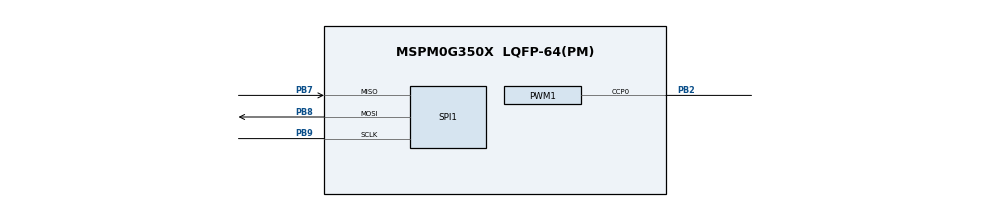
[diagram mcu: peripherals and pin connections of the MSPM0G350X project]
/**
 * @cliArgs --device "MSPM0G350X" --package "LQFP-64(PM)" --part "Default" --product "mspm0_sdk@2.00.01.00"
 * @versions {"tool":"1.20.0+3587"}
 */

/**
 * Import the modules used in this configuration.
 */
const GPIO   = scripting.addModule("/ti/driverlib/GPIO", {}, false);
const GPIO1  = GPIO.addInstance();
const PWM    = scripting.addModule("/ti/driverlib/PWM", {}, false);
const PWM1   = PWM.addInstance();
const SPI    = scripting.addModule("/ti/driverlib/SPI", {}, false);
const SPI1   = SPI.addInstance();
const SYSCTL = scripting.addModule("/ti/driverlib/SYSCTL");

/**
 * Write custom configuration values to the imported modules.
 */
GPIO1.$name                                 = "KEY";
GPIO1.port                                  = "PORTB";
GPIO1.associatedPins.create(2);
GPIO1.associatedPins[0].$name               = "freq";
GPIO1.associatedPins[0].direction           = "INPUT";
GPIO1.associatedPins[0].assignedPin         = "15";
GPIO1.associatedPins[0].interruptEn         = true;
GPIO1.associatedPins[0].polarity            = "RISE";
GPIO1.associatedPins[0].internalResistor    = "PULL_UP";
GPIO1.associatedPins[1].$name               = "duty";
GPIO1.associatedPins[1].direction           = "INPUT";
GPIO1.associatedPins[1].assignedPin         = "16";
GPIO1.associatedPins[1].assignedPortSegment = "Upper";
GPIO1.associatedPins[1].interruptEn         = true;
GPIO1.associatedPins[1].internalResistor    = "PULL_UP";
GPIO1.associatedPins[1].polarity            = "RISE";

const Board = scripting.addModule("/ti/driverlib/Board", {}, false);

PWM1.$name                      = "PWM_0";
PWM1.timerCount                 = 125;
PWM1.clockPrescale              = 256;
PWM1.ccIndex                    = [0];
PWM1.peripheral.$assign         = "TIMG6";
PWM1.peripheral.ccp0Pin.$assign = "PB2";
PWM1.PWM_CHANNEL_0.$name        = "ti_driverlib_pwm_PWMTimerCC0";
PWM1.PWM_CHANNEL_0.dutyCycle    = 50;
PWM1.ccp0PinConfig.$name        = "ti_driverlib_gpio_GPIOPinGeneric5";

SPI1.$name                              = "SPI1";
SPI1.targetBitRate                      = 800000;
SPI1.frameFormat                        = "MOTO3";
SPI1.peripheral.$assign                 = "SPI1";
SPI1.peripheral.sclkPin.$assign         = "PB9";
SPI1.peripheral.mosiPin.$assign         = "PB8";
SPI1.peripheral.misoPin.$assign         = "PB7";
SPI1.sclkPinConfig.direction            = scripting.forceWrite("OUTPUT");
SPI1.sclkPinConfig.onlyInternalResistor = scripting.forceWrite(false);
SPI1.sclkPinConfig.passedPeripheralType = scripting.forceWrite("Digital");
SPI1.sclkPinConfig.$name                = "ti_driverlib_gpio_GPIOPinGeneric0";
SPI1.mosiPinConfig.direction            = scripting.forceWrite("OUTPUT");
SPI1.mosiPinConfig.hideOutputInversion  = scripting.forceWrite(false);
SPI1.mosiPinConfig.onlyInternalResistor = scripting.forceWrite(false);
SPI1.mosiPinConfig.passedPeripheralType = scripting.forceWrite("Digital");
SPI1.mosiPinConfig.$name                = "ti_driverlib_gpio_GPIOPinGeneric1";
SPI1.misoPinConfig.onlyInternalResistor = scripting.forceWrite(false);
SPI1.misoPinConfig.passedPeripheralType = scripting.forceWrite("Digital");
SPI1.misoPinConfig.$name                = "ti_driverlib_gpio_GPIOPinGeneric2";

SYSCTL.forceDefaultClkConfig = true;

/**
 * Pinmux solution for unlocked pins/peripherals. This ensures that minor changes to the automatic solver in a future
 * version of the tool will not impact the pinmux you originally saw.  These lines can be completely deleted in order to
 * re-solve from scratch.
 */
GPIO1.associatedPins[0].pin.$suggestSolution = "PB15";
GPIO1.associatedPins[1].pin.$suggestSolution = "PB16";
Board.peripheral.$suggestSolution            = "DEBUGSS";
Board.peripheral.swclkPin.$suggestSolution   = "PA20";
Board.peripheral.swdioPin.$suggestSolution   = "PA19";
SYSCTL.peripheral.$suggestSolution           = "SYSCTL";
